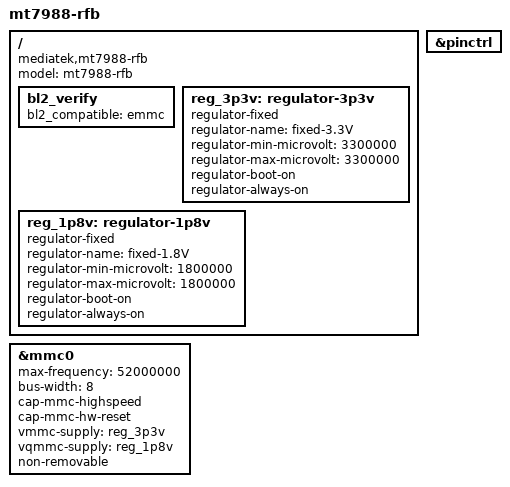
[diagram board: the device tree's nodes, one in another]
// SPDX-License-Identifier: GPL-2.0
/*
 * Copyright (c) 2022 MediaTek Inc.
 * Author: Sam Shih <sam.shih@mediatek.com>
 */

/dts-v1/;
#include "mt7988-rfb.dts"
#include <dt-bindings/gpio/gpio.h>

/ {
	model = "mt7988-rfb";
	compatible = "mediatek,mt7988-rfb", "mediatek,mt7988-emmc-rfb";

	bl2_verify {
		bl2_compatible = "emmc";
	};

	reg_3p3v: regulator-3p3v {
		compatible = "regulator-fixed";
		regulator-name = "fixed-3.3V";
		regulator-min-microvolt = <3300000>;
		regulator-max-microvolt = <3300000>;
		regulator-boot-on;
		regulator-always-on;
	};

	reg_1p8v: regulator-1p8v {
		compatible = "regulator-fixed";
		regulator-name = "fixed-1.8V";
		regulator-min-microvolt = <1800000>;
		regulator-max-microvolt = <1800000>;
		regulator-boot-on;
		regulator-always-on;
	};
};

&pinctrl {
	/*mmc0_pins_default: mmc0default {
		mux {
			function = "flash";
			groups =  "emmc_51";
		};

		conf-cmd-dat {
			pins = "EMMC_DATA_0", "EMMC_DATA_1", "EMMC_DATA_2",
			       "EMMC_DATA_3", "EMMC_DATA_4", "EMMC_DATA_5",
			       "EMMC_DATA_6", "EMMC_DATA_7", "EMMC_CMD";
			input-enable;
		};

		conf-clk {
			pins = "EMMC_CK";
		};

		conf-dsl {
			pins = "EMMC_DSL";
		};

		conf-rst {
			pins = "EMMC_RSTB";
		};
	};*/
};

&mmc0 {
	//pinctrl-names = "default";
	//pinctrl-0 = <&mmc0_pins_default>;
	max-frequency = <52000000>;
	bus-width = <8>;
	cap-mmc-highspeed;
	cap-mmc-hw-reset;
	vmmc-supply = <&reg_3p3v>;
	vqmmc-supply = <&reg_1p8v>;
	non-removable;
	status = "okay";
};
